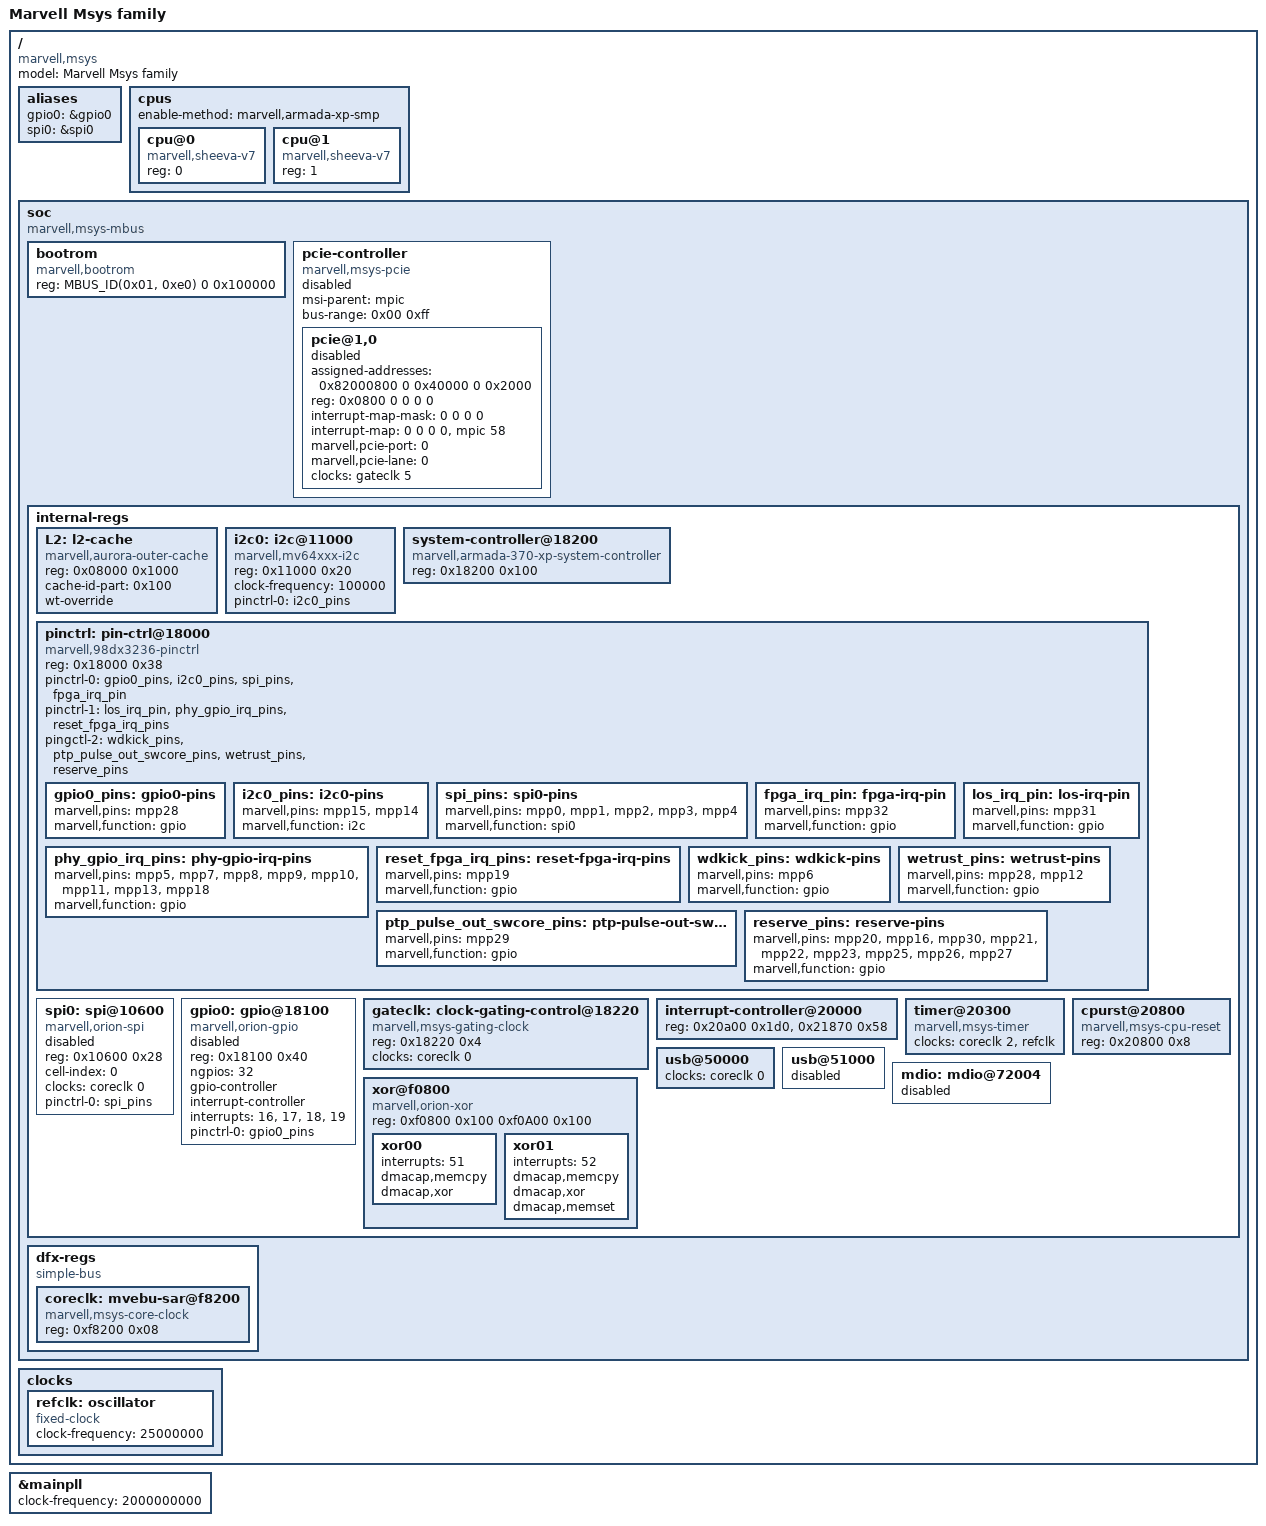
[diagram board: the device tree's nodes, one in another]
/*
 * Device Tree Include file for Marvell Armada 370 family SoC
 *
 * Copyright (C) 2012 Marvell
 *
 * Lior Amsalem <alior@marvell.com>
 * Gregory CLEMENT <gregory.clement@free-electrons.com>
 * Thomas Petazzoni <thomas.petazzoni@free-electrons.com>
 *
 * This file is licensed under the terms of the GNU General Public
 * License version 2.  This program is licensed "as is" without any
 * warranty of any kind, whether express or implied.
 *
 * Contains definitions specific to the Armada 370 SoC that are not
 * common to all Armada SoCs.
 */

#include "armada-370-xp.dtsi"
/include/ "skeleton.dtsi"

/ {
	model = "Marvell Msys family";
	compatible = "marvell,msys", "marvell,armada-370-xp";

	aliases {
		gpio0 = &gpio0;
		spi0 = &spi0;
	};

	cpus {
		#address-cells = <1>;
		#size-cells = <0>;
		enable-method = "marvell,armada-xp-smp";

		cpu@0 {
			device_type = "cpu";
			compatible = "marvell,sheeva-v7";
			reg = <0>;
		};

		cpu@1 {
			device_type = "cpu";
			compatible = "marvell,sheeva-v7";
			reg = <1>;
		};
	};

	soc {
		compatible = "marvell,msys-mbus", "marvell,armada370-mbus", "simple-bus";

		bootrom {
			compatible = "marvell,bootrom";
			reg = <MBUS_ID(0x01, 0xe0) 0 0x100000>;
		};

		pcie-controller {
			compatible = "marvell,msys-pcie", "marvell,armada-370-pcie";
			status = "disabled";
			device_type = "pci";

			#address-cells = <3>;
			#size-cells = <2>;

			msi-parent = <&mpic>;
			bus-range = <0x00 0xff>;

			ranges =
				<0x82000000 0 0x40000 MBUS_ID(0xf0, 0x01) 0x40000 0 0x00002000 /* Port 0.0 registers */
				/*0x82000000 0 0x80000 MBUS_ID(0xf0, 0x01) 0x80000 0 0x00002000 */ /* Port 1.0 registers */
				0x82000000 0x1 0     MBUS_ID(0x04, 0xe8) 0       1 0 /* Port 0.0 MEM */
				0x81000000 0x1 0     MBUS_ID(0x04, 0xe0) 0       1 0 /* Port 0.0 IO  */
				0x82000000 0x2 0     MBUS_ID(0x04, 0xd8) 0 1 0 /* Port 0.1 MEM */
				0x81000000 0x2 0     MBUS_ID(0x04, 0xd0) 0 1 0 /* Port 0.1 IO  */
				/*0x82000000 0x3 0     MBUS_ID(0x04, 0xb8) 0 1 0 * Port 0.2 MEM *
				0x81000000 0x3 0     MBUS_ID(0x04, 0xb0) 0 1 0 * Port 0.2 IO  *
				0x82000000 0x4 0     MBUS_ID(0x04, 0x78) 0 1 0 * Port 0.3 MEM *
				0x81000000 0x4 0     MBUS_ID(0x04, 0x70) 0 1 0 * Port 0.3 IO  */ >;

			pcie@1,0 {
				device_type = "pci";
				assigned-addresses = <0x82000800 0 0x40000 0 0x2000>;
				reg = <0x0800 0 0 0 0>;
				#address-cells = <3>;
				#size-cells = <2>;
				#interrupt-cells = <1>;
                                ranges = <0x82000000 0 0 0x82000000 0x1 0 1 0
                                          0x81000000 0 0 0x81000000 0x1 0 1 0>;
				interrupt-map-mask = <0 0 0 0>;
				interrupt-map = <0 0 0 0 &mpic 58>;
				marvell,pcie-port = <0>;
				marvell,pcie-lane = <0>;
				clocks = <&gateclk 5>;
				status = "disabled";
			};
		};

		internal-regs {
			L2: l2-cache {
				compatible = "marvell,aurora-outer-cache";
				reg = <0x08000 0x1000>;
				cache-id-part = <0x100>;
				wt-override;
			};

			i2c0: i2c@11000 {
				compatible = "marvell,mv64xxx-i2c";
				reg = <0x11000 0x20>;
				clock-frequency = <100000>;

				pinctrl-0 = <&i2c0_pins>;
				pinctrl-names = "default";
			};

			system-controller@18200 {
				compatible = "marvell,armada-370-xp-system-controller";
				reg = <0x18200 0x100>;
			};

			pinctrl: pin-ctrl@18000 {
				reg = <0x18000 0x38>;
				compatible = "marvell,98dx3236-pinctrl";
				pinctrl-0 = <&gpio0_pins &i2c0_pins &spi_pins &fpga_irq_pin>;
				pinctrl-1 = <&los_irq_pin &phy_gpio_irq_pins &reset_fpga_irq_pins>;
				pingctl-2 = <&wdkick_pins &ptp_pulse_out_swcore_pins &wetrust_pins &reserve_pins>;
				pinctrl-names = "default";

				gpio0_pins: gpio0-pins {
					marvell,pins = "mpp28";
					marvell,function = "gpio";
				};

				i2c0_pins: i2c0-pins {
					marvell,pins = "mpp15", "mpp14";
					marvell,function = "i2c";
				};

				spi_pins: spi0-pins {
					marvell,pins = "mpp0", "mpp1", "mpp2", "mpp3", "mpp4";
					marvell,function = "spi0";
				};

				fpga_irq_pin: fpga-irq-pin {
					marvell,pins = "mpp32";
					marvell,function = "gpio";
				};

				los_irq_pin: los-irq-pin {
					marvell,pins = "mpp31";
					marvell,function = "gpio";
				};

				phy_gpio_irq_pins: phy-gpio-irq-pins {
					marvell,pins = "mpp5", "mpp7", "mpp8", "mpp9", "mpp10", "mpp11", "mpp13", "mpp18";
					marvell,function = "gpio";
				};
				
				reset_fpga_irq_pins: reset-fpga-irq-pins {
					marvell,pins = "mpp19";
					marvell,function = "gpio";
				};

				wdkick_pins: wdkick-pins {
					marvell,pins = "mpp6";
					marvell,function = "gpio";
				};

				ptp_pulse_out_swcore_pins: ptp-pulse-out-swcore-pins {
					marvell,pins = "mpp29";
					marvell,function = "gpio";
				};

				wetrust_pins: wetrust-pins {
					marvell,pins = "mpp28", "mpp12";
					marvell,function = "gpio";
				};

				reserve_pins: reserve-pins {
					marvell,pins = "mpp20", "mpp16", "mpp30", "mpp21", "mpp22", "mpp23", "mpp25", "mpp26", "mpp27";
					marvell,function = "gpio";
				};
			};

			spi0: spi@10600 {
				compatible = "marvell,orion-spi";
				reg = <0x10600 0x28>;
				#address-cells = <1>;
				#size-cells = <0>;
				cell-index = <0>;
				clocks = <&coreclk 0>;

				pinctrl-0 = <&spi_pins>;
				pinctrl-names = "default";
				status = "disabled";
			};

			gpio0: gpio@18100 {
				compatible = "marvell,orion-gpio";
				reg = <0x18100 0x40>;
				ngpios = <32>;
				gpio-controller;
				#gpio-cells = <2>;
				interrupt-controller;
				#interrupt-cells = <2>;
				interrupts = <16>, <17>, <18>, <19>;

				pinctrl-0 = <&gpio0_pins>;
				pinctrl-names = "default";
				status = "disabled";
			};

			gateclk: clock-gating-control@18220 {
				compatible = "marvell,msys-gating-clock";
				reg = <0x18220 0x4>;
				clocks = <&coreclk 0>;
				#clock-cells = <1>;
			};

			interrupt-controller@20000 {
				reg = <0x20a00 0x1d0>, <0x21870 0x58>;
			};

			timer@20300 {
				compatible = "marvell,msys-timer";
				clocks = <&coreclk 2>, <&refclk>;
				clock-names = "nbclk", "fixed";
			};

			cpurst@20800 {
				compatible = "marvell,msys-cpu-reset";
				reg = <0x20800 0x8>;
			};

			usb@50000 {
				clocks = <&coreclk 0>;
			};

			usb@51000 {
				status = "disabled";
			};

			mdio: mdio@72004 {
				status = "disabled";
			};

			xor@f0800 {
				compatible = "marvell,orion-xor";
				reg = <0xf0800 0x100
				       0xf0A00 0x100>;
				status = "okay";

				xor00 {
					interrupts = <51>;
					dmacap,memcpy;
					dmacap,xor;
				};
				xor01 {
					interrupts = <52>;
					dmacap,memcpy;
					dmacap,xor;
					dmacap,memset;
				};
			};
		};

		dfx-regs {
			compatible = "simple-bus";
			#address-cells = <1>;
			#size-cells = <1>;
			ranges = <0 MBUS_ID(0x08, 0x00) 0 0x100000>;

			coreclk: mvebu-sar@f8200 {
				compatible = "marvell,msys-core-clock";
				reg = <0xf8200 0x08>;
				#clock-cells = <1>;
			};
		};
	};

	clocks {
		refclk: oscillator {
			compatible = "fixed-clock";
			#clock-cells = <0>;
			clock-frequency = <25000000>;
		};
	};
};

&mainpll {
	/* PLL input is 2.0 GHz on msys */
	clock-frequency = <2000000000>;
};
